# D1H register map
Vendor: Allwinner; File version: 1.0
Registers are 32-bit, read-write, reset 0x0 unless marked. A register's access mark holds for its fields unless they carry their own. Offsets are from the block's base; [hi:lo] are bit positions; {n}, {i} and the like mark numbered series; 'fields as' and 'values as' point back to an identical list.

## IOMMU — I/O Memory Management Unit
Base 0x02010000
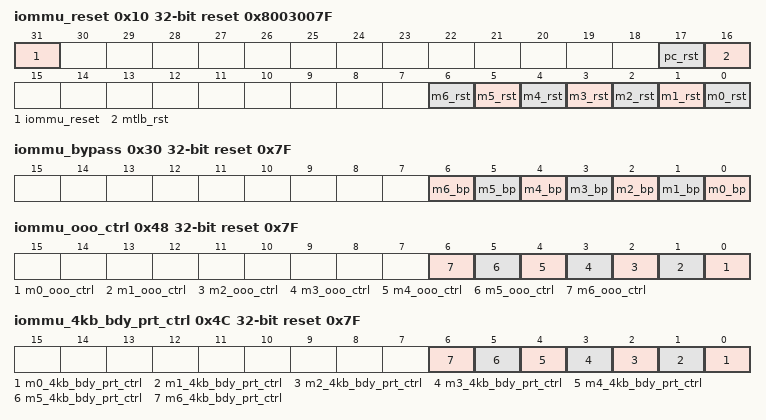
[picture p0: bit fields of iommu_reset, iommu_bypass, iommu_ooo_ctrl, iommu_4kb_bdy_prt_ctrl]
0x10 iommu_reset reset 0x8003007F (reset mask 0x8003007F)
  [all] fields
    0=SET (Set reset signal); 1=R_ELEASE (Release reset signal)
  [31] iommu_reset — IOMMU Software Reset Switch、n. Before IOMMU software reset operation, ensure IOMMU never be opened; or all bus operations are completed; or DRAM and the peripherals have opened the corresponding switch, for shielding the effects of IOMMU reset.
  [17] pc_rst — PTW Cache Reset . PTW Cache address convert lane software reset switch. . When PTW Cache occurs abnormal, the bit is used to reset PTW Cache individually.
  [16] mtlb_rst — Macrotlb Reset . Macro TLB address convert lane software reset switch. . When PTW Cache occurs abnormal, the bit is used to reset PTW Cache individually.
  [n] m{n}_rst (n=0..6) — Master[i] Reset . Master[i] address convert lane software reset switch. . When Master[i] occurs abnormal, the bit is used to reset PTW Cache individually.
0x20 iommu_enable
  [0] enable — IOMMU module enable switch . Before IOMMU address mapping function opens, configure the Translation Table Base register; or ensure all masters are in bypass status or no the status of sending bus demand(such as reset)
    0=DISABLE (Disable IOMMU); 1=ENABLE (Enable IOMMU)
0x30 iommu_bypass reset 0x7F (reset mask 0x7F)
  [n] m{n}_bp (n=0..6) — Master[i] bypass switch . After bypass function is opened, IOMMU can not map the address of Master6 sending, and directly output the virtual address to MBUS as physical address.
    0=DISABLE (Disable bypass function); 1=ENABLE (Enable bypass function)
0x40 iommu_auto_gating reset 0x1
  [0] iommu_auto_gating — IOMMU circuit auto gating control . The purpose is to decrease power consumption of the module.
    0=DISABLE (Disable auto gating function); 1=ENABLE (Enable auto gating function)
0x44 iommu_wbuf_ctrl reset 0x7F (reset mask 0x7F) — IOMMU Write Buffer Control Register
0x48 iommu_ooo_ctrl reset 0x7F (reset mask 0x7F) — IOMMU Out of Order Control Register
  [n] m{n}_ooo_ctrl (n=0..6) — Master[i] out-of-order control bit
    0=DISABLE (Disable out-of-order); 1=ENABLE (Enable out-of-order)
0x4C iommu_4kb_bdy_prt_ctrl reset 0x7F (reset mask 0x7F) — IOMMU 4KB Boundary Protect Control Register
  [n] m{n}_4kb_bdy_prt_ctrl (n=0..6) — Master[i] 4 KB boundary protect control bit
    0=DISABLE (Disable 4 KB boundary protect); 1=ENABLE (Enable 4 KB boundary protect)
0x50 iommu_ttb — IOMMU Translation Table Base Register
  [31:14] ttb — Translation Table Base . Level1 page table starting address, aligned to 16 KB. . When operating the register, IOMMU address mapping function must be closed, namely IOMMU_ENABLE is 0; Or Bypass function of all main equipment is set to 1, or no the state of transfer bus commands (such as setting).
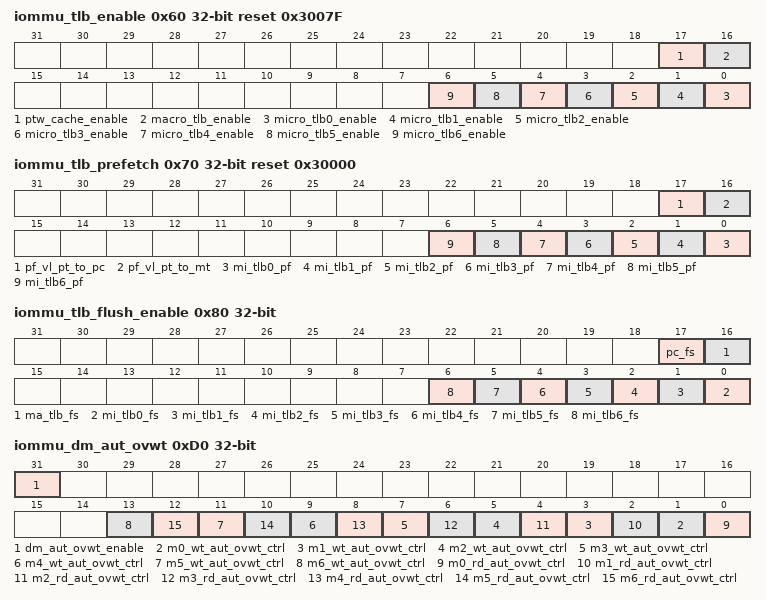
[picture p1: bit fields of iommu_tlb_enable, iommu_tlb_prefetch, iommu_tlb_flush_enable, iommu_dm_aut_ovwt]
0x60 iommu_tlb_enable reset 0x3007F (reset mask 0x3007F)
  [all] fields
    0=DISABLE; 1=ENABLE
  [17] ptw_cache_enable — PTW Cache enable bit
  [16] macro_tlb_enable — Macro TLB enable bit
  [n] micro_tlb{n}_enable (n=0..6) — Micro TLB[i] enable bit
0x70 iommu_tlb_prefetch reset 0x30000 (reset mask 0x3007F)
  [17] pf_vl_pt_to_pc — Prefetch Value Pagetable to PTW Cache . If the function is enabled, the prefetch function will not update the invalid Level1 page table to PTW cache.
    0=DISABLE; 1=ENABLE (Enable If the function is enabled, the prefetch function will not update the invalid Level1 page table to PTW cache.)
  [16] pf_vl_pt_to_mt — Prefetch Value Pagetable to Macro TLB . If the function is enabled, the prefetch function will not update the invalid Level2 page table to Macro TLB.
    0=DISABLE; 1=ENABLE (Enable If the function is enabled, the prefetch function will not update the invalid Level2 page table to Macro TLB.)
  [n] mi_tlb{n}_pf (n=0..6) — Micro TLB6 prefetch enable
    0=DISABLE; 1=ENABLE
0x80 iommu_tlb_flush_enable
  [all] fields
    0=NO_CLEAR_OR_COMPLETED (No clear operation or clear operation is completed); 1=ENABLE (Enable clear operation)
  [17] pc_fs — PTW Cache Flush Clear PTW Cache . After the Flush operation is completed, the bit can clear automatically.
  [16] ma_tlb_fs — Macro TLB Flush . Clear Macro TLB . After the Flush operation is completed, the bit can clear automatically.
  [n] mi_tlb{n}_fs (n=0..6) — Micro TLB[i] Flush Clear Micro TLB6 . After the Flush operation is completed, the bit can clear automatically.
0x84 iommu_tlb_ivld_mode_sel — IOMMU TLB Invalidation Mode Select Register
  [0] tlb_ivld_mode_sel
    0=M_ASK_MODE (Invalidate TLB by using the Mask mode); 1=S_TART_END_MODE (Invalidate TLB by using the Start and End mode)
0x88 iommu_tlb_ivld_sta_addr — IOMMU TLB Invalidation Start Address Register
  [31:12] tlb_ivld_sta_addr — TLB invalid start address, 4 KB aligned.
0x8C iommu_tlb_ivld_end_addr — IOMMU TLB Invalidation End Address Register
  [31:12] tlb_ivld_end_addr — TLB invalid end address, 4 KB aligned.
0x90 iommu_tlb_ivld_addr — IOMMU TLB Invalidation Address Register
  [31:12] tlb_ivld_addr — TLB invalid address, 4 KB aligned
0x94 iommu_tlb_ivld_addr_mask — IOMMU TLB Invalidation Address Mask Register
  [31:12] tlb_ivld_addr_mask — TLB invalid address mask register, 4 KB aligned
0x98 iommu_tlb_ivld_enable — IOMMU TLB Invalidation Enable Register
  [0] tlb_ivld_enable — Enable TLB invalidation operation . After invalidation operation is completed, the bit can clear automatically. . When operating invalidation operation, TLB/Cache operation has not affected. . After or before invalidation operation starts, there is no absolute relationship between the same address switch operation and invalidation operation.
    0=NO_OPERATION_OR_COMPLETED (No operation or operation is completed); 1=ENABLE (Enable invalidation operation)
0x9C iommu_pc_ivld_mode_sel — IOMMU PC Invalidation Mode Select Register
  [0] pc_ivld_mode_sel — PTW Cache Invalid Mode Select
    0=M_ASK_MODE (Invalidate PTW by using the Mask mode); 1=S_TART_END_MODE (Invalidate PTW by using the Start and End mode)
0xA0 iommu_pc_ivld_addr — IOMMU PC Invalidation Address Register
  [31:20] pc_ivld_addr — PTW Cache invalid address, 1 MB aligned.
0xA4 iommu_pc_ivld_sta_addr — IOMMU PC Invalidation Start Address Register
  [31:20] pc_ivld_sa — PTW Cache invalid start address, 1 MB aligned.
0xA8 iommu_pc_ivld_enable — IOMMU PC Invalidation Enable Register
  [0] pc_ivld_enable — Enable PTW Cache invalidation operation . After invalidation operation is completed, the bit can clear automatically. . After or before invalidation operation starts, there is no absolute relationship between the same address switch operation and invalidation operation.
    values as iommu_tlb_ivld_enable.tlb_ivld_enable
0xAC iommu_pc_ivld_end_addr — IOMMU PC Invalidation End Address Register
  [31:20] pc_ivld_ea — PTW Cache invalid end address, 1 MB aligned.
{0xB0+4i} iommu_dm_aut_ctrl{i} (i=0..7) — IOMMU Domain Authority Control [i] Register . Software can set 15 different permission control types in IOMMU_DM_AUT_CTRL0-7. A default access control type is DOMAIN0. The read/write operation of DOMAIN1-15 is unlimited by default. . Software needs to set the index of the permission control domain corresponding to the page table item in the bit[7:4] of the Level2 page table, the default value is 0 (use domain 0), that is, the read/write operation is not controlled. . Setting REG_ARD_OVWT can mask the Domain control defined by IOMMU_DM_AUT_CTRL0-7. All Level2 page table type are covered by the type of REG_ARD_OVWT. The read/write operation is permitted by default.
  [2n+17] dm1_m{n}_wt_aut_ctrl (n=0..6) — Domain [i + 1] write permission control for master [j]
    0=PERMITTED (The write-operation is permitted); 1=PROHIBITED (The write-operation is prohibited)
  [2n+17] dm1_m{n}_rd_aut_ctrl (n=0..6) — Domain [i + 1] read permission control for master [j]
    0=PERMITTED (The read-operation is permitted); 1=PROHIBITED (The read-operation is prohibited)
  [2n+17] dm0_m{n}_wt_aut_ctrl (n=0..6) — Domain [i] write permission control for master [j]
    values as dm1_m0_wt_aut_ctrl
  [2n+17] dm0_m{n}_rd_aut_ctrl (n=0..6) — Domain [i] read permission control for master [j]
    values as dm1_m0_rd_aut_ctrl
0xD0 iommu_dm_aut_ovwt — IOMMU Domain Authority Overwrite Register
  [31] dm_aut_ovwt_enable — Domain write/read permission overwrite enable
    0=DISABLE; 1=ENABLE
  [2n+1] m{n}_wt_aut_ovwt_ctrl (n=0..6) — Master[i] write permission overwrite control
    values as iommu_dm_aut_ctrl0.dm1_m0_wt_aut_ctrl
  [2n] m{n}_rd_aut_ovwt_ctrl (n=0..6) — Master[i] read permission overwrite control
    values as iommu_dm_aut_ctrl0.dm1_m0_rd_aut_ctrl
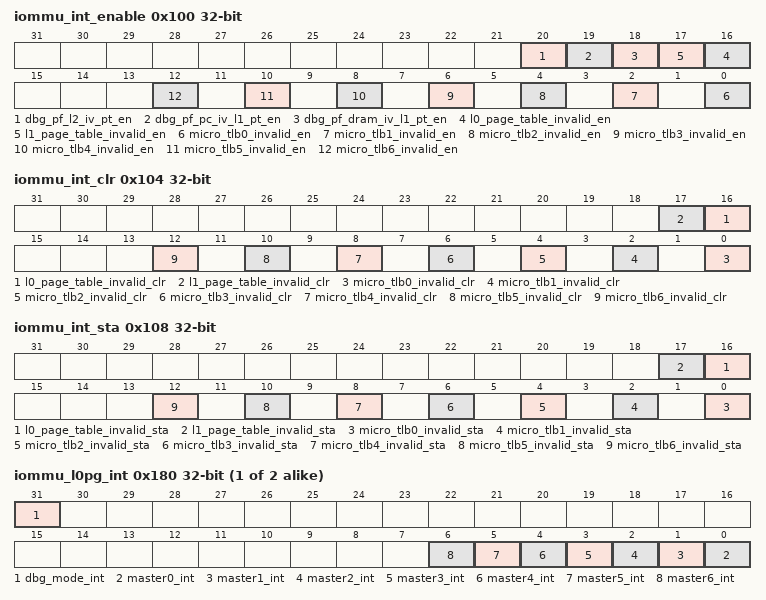
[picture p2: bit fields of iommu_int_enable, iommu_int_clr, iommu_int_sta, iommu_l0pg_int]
0x100 iommu_int_enable — IOMMU Interrupt Enable Register
  [all] fields
    0=M_ASK (Mask interrupt); 1=ENABLE (Enable interrupt)
  [20] dbg_pf_l2_iv_pt_en — Debug or Prefetch Invalid Page Table Enable
  [19] dbg_pf_pc_iv_l1_pt_en — Debug or Prefetch PTW Cache Invalid Level1 Page Table Enable
  [18] dbg_pf_dram_iv_l1_pt_en — Debug or Prefetch DRAM Invalid Level1 Page Table Enable
  [n+16] l{n}_page_table_invalid_en (n=0..1) — Level[i] page table invalid interrupt enable
  [2n] micro_tlb{n}_invalid_en (n=0..6) — Micro TLB[i] permission invalid interrupt enable
0x104 iommu_int_clr — IOMMU Interrupt Clear Register
  [n+16] l{n}_page_table_invalid_clr (n=0..1) wo — Level[i] page table invalid interrupt clear bit
    0=INVALID (Invalid operation); 1=CLEAR (Clear interrupt)
  [2n] micro_tlb{n}_invalid_clr (n=0..6) wo — Micro TLB[i] permission invalid interrupt clear bit
    0=INVALID (Invalid operation); 1=CLEAR (Clear interrupt Note: The bit is not used.)
0x108 iommu_int_sta — IOMMU Interrupt Status Register
  [n+16] l{n}_page_table_invalid_sta (n=0..1) ro — Level[i] page table invalid interrupt status bit
    0=NOT_HAPPEN_OR_CLEARED (Interrupt does not happen or interrupt is cleared); 1=HAPPENS (Interrupt happens)
  [2n] micro_tlb{n}_invalid_sta (n=0..6) ro — Micro TLB[i] permission invalid interrupt status bit
    values as l0_page_table_invalid_sta
{0x110+4i} iommu_int_err_addr_tlb{i} (i=0..6) ro — IOMMU Interrupt Error Address [i]
  [31:0] int_err_addr — Virtual address that caused Micro TLB[i] to interrupt
{0x130+4i} iommu_int_err_addr_l{i} (i=0..1) ro — IOMMU Interrupt Error Address L[i]
  [31:0] int_err_addr — Virtual address that caused L[i] page table to interrupt
{0x150+4i} iommu_int_err_data_tlb{i} (i=0..6) ro — IOMMU Interrupt Error Data [i] Register
  [31:0] int_err_data — Corresponding page table of virtual address that caused Micro TLB[i] to interrupt
{0x170+4i} iommu_int_err_data_l{i} (i=0..1) ro — IOMMU Interrupt Error Data L[i] Register
  [31:0] int_err_data — Corresponding page table of virtual address that caused L[i] page table to interrupt
{0x180+4i} iommu_l{i}pg_int (i=0..1) ro — IOMMU L[i] Page Table Interrupt Register
  [31] dbg_mode_int — Debug mode address switch causes L[i] page table to occur interrupt
  [n] master{n}_int (n=0..6) — Master[j] address switch causes L[i] page table to occur interrupt
0x190 iommu_va — IOMMU Virtual Address Register
  [31:0] va — Virtual address of read/write
0x194 iommu_va_data — IOMMU Virtual Address Data Register
  [31:0] va_data — Data corresponding to read/write virtual address
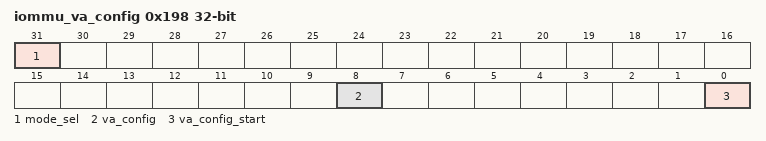
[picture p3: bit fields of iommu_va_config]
0x198 iommu_va_config — IOMMU Virtual Address Configuration Register
  [31] mode_sel
    0=P_REFETCH; 1=D_EBUG (Debug Mode)
  [8] va_config — Virtual Address Configuration
    0=R_EAD (Read operation); 1=W_RITE (Write operation)
  [0] va_config_start
    0=NO_OPERATION_OR_COMPLETED (No operation or operation is completed); 1=S_TART
0x200 iommu_pmu_enable
  [0] pmu_enable
    0=DISABLE (Disable statistical function); 1=ENABLE (Enable statistical function)
0x210 iommu_pmu_clr — IOMMU PMU Clear Register
  [0] pmu_clr
    0=NO_CLEAR_OR_COMPLETED (No clear operation or clear operation is completed); 1=CLEAR (Clear counter data)
{0x230+0x10*i} iommu_pmu_access_low{i} (i=0..8) — IOMMU PMU Access Low [i] Register
{0x234+0x10*i} iommu_pmu_access_high{i} (i=0..8) — IOMMU PMU Access High [i] Register
{0x238+0x10*i} iommu_pmu_hit_low{i} (i=0..8) — IOMMU PMU Hit Low [i] Register
{0x23C+0x10*i} iommu_pmu_hit_high{i} (i=0..8) — IOMMU PMU Hit High [i] Register
{0x300+0x10*i} iommu_pmu_tl_low{i} (i=0..6) — IOMMU Total Latency Low [i] Register
{0x304+0x10*i} iommu_pmu_tl_high{i} (i=0..6) — IOMMU Total Latency High [i] Register
{0x308+0x10*i} iommu_pmu_ml{i} (i=0..6) — IOMMU Max Latency [i] Register
